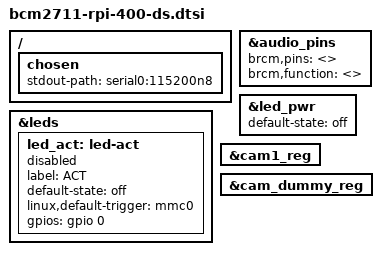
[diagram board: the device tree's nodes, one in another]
// SPDX-License-Identifier: GPL-2.0

// =============================================
// Downstream rpi- changes

/ {
	chosen {
		stdout-path = "serial0:115200n8";
	};
};

&audio_pins {
	brcm,pins = <>;
	brcm,function = <>;
};

// Declare the LED but leave it disabled, in case a user wants to map it
// to a GPIO on the header
&leds {
	led_act: led-act {
		label = "ACT";
		default-state = "off";
		linux,default-trigger = "mmc0";
		gpios = <&gpio 0 GPIO_ACTIVE_HIGH>;
		status = "disabled";
	};
};

&led_pwr {
	default-state = "off";
};

&cam1_reg {
	  /delete-property/ gpio;
};

cam0_reg: &cam_dummy_reg {
};

/ {
	__overrides__ {
		audio = <&chosen>,"bootargs{on='snd_bcm2835.enable_hdmi=1',off='snd_bcm2835.enable_hdmi=0'}";

		act_led_gpio = <&led_act>,"gpios:4",
			       <&led_act>,"status=okay";
		act_led_activelow = <&led_act>,"gpios:8";
		act_led_trigger = <&led_act>,"linux,default-trigger";
		eth_max_speed = <&phy1>,"max-speed:0";
		pwr_led_gpio = <&led_pwr>,"gpios:4";
		pwr_led_activelow = <&led_pwr>,"gpios:8";
		pwr_led_trigger = <&led_pwr>,"linux,default-trigger";
	};
};
